# STM32G0B1 register map
File version: 1.8
CPU: CM0 r0p1, little endian, MPU, no FPU, 2 interrupt priority bits
Registers are 32-bit, read-write, reset 0x0 unless marked. A register's access mark holds for its fields unless they carry their own. Offsets are from the block's base; [hi:lo] are bit positions; {n}, {i} and the like mark numbered series; 'fields as' and 'values as' point back to an identical list.

## SYSCFG — System configuration controller
Base 0x40010000
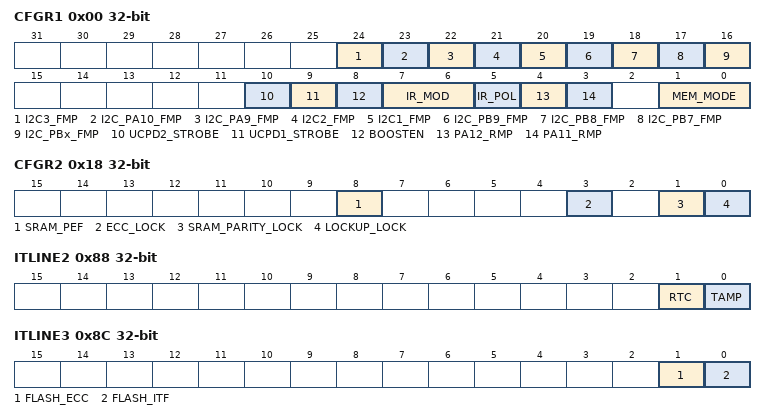
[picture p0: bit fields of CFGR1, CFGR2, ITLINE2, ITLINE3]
0x00 CFGR1 — SYSCFG configuration register 1
  [24] I2C3_FMP
    0=Disabled (Uses normal GPIO drive); 1=Enabled (Uses I2C FastMode+ drive)
  [23] I2C_PA10_FMP — Fast Mode Plus (FM+) driving capability activation bits
    values as I2C3_FMP
  [22] I2C_PA9_FMP — Fast Mode Plus (FM+) driving capability activation bits
    values as I2C3_FMP
  [21] I2C2_FMP — FM+ driving capability activation for I2C2
    values as I2C3_FMP
  [20] I2C1_FMP — FM+ driving capability activation for I2C1
    values as I2C3_FMP
  [19] I2C_PB9_FMP
    values as I2C3_FMP
  [18] I2C_PB8_FMP
    values as I2C3_FMP
  [17] I2C_PB7_FMP
    values as I2C3_FMP
  [16] I2C_PBx_FMP — Fast Mode Plus (FM+) driving capability activation bits
    values as I2C3_FMP
  [10] UCPD2_STROBE — Strobe signal bit for UCPD2
    1=Disconnect the UCPD pull-down resistors
  [9] UCPD1_STROBE — Strobe signal bit for UCPD1
    1=Disconnect the UCPD pull-down resistors
  [8] BOOSTEN — I/O analog switch voltage booster enable
    0=VDD (supply analog switches from VDD); 1=BOOST (supply analog switches from dedicated voltage booster)
  [7:6] IR_MOD — IR Modulation Envelope signal selection.
    0=TIM16 (IR modulation envelope from TIM16); 1=USART1 (IR modulation envelope from USART1); 2=USART4 (IR modulation envelope from USART4)
  [5] IR_POL — IR output polarity selection
    0=Normal (Output of IRTIM is not inverted); 1=Inverted (Output of IRTIM is inverted)
  [4] PA12_RMP — PA11 and PA12 remapping bit.
    0=Normal (PA12 pin connected to PA12 GPIO); 1=Remap (PA12 pin connected to PA10 GPIO)
  [3] PA11_RMP
    0=Normal (PA11 pin connected to PA11 GPIO); 1=Remap (PA11 pin connected to PA9 GPIO)
  [1:0] MEM_MODE — Memory mapping selection bits
    0=Main flash memory mapped at zero address; 2=System flash memory mapped at zero address; 3=SRAM (Embedded SRAM mapped at zero address)
0x18 CFGR2 — SYSCFG configuration register 1
  [8] SRAM_PEF — SRAM parity error flag
    0=Normal (No SRAM parity error detected); 1=Error (SRAM parity error detected)
  [3] ECC_LOCK — ECC error lock bit
    0=Disabled (error not connected to timers); 1=Enabled (error triggers TIM1/15/16/17 break input)
  [1] SRAM_PARITY_LOCK — SRAM parity lock bit
    values as ECC_LOCK
  [0] LOCKUP_LOCK — Cortex-M0+ LOCKUP bit enable bit
    values as ECC_LOCK
0x80 ITLINE0 ro — interrupt line 0 status register
  [0] WWDG — Window watchdog interrupt pending flag
    0=NotInterrupted (Interrupt not triggered); 1=Interrupted (Interrup triggered)
0x88 ITLINE2 ro — interrupt line 2 status register
  [1] RTC
    values as ITLINE0.WWDG
  [0] TAMP
    values as ITLINE0.WWDG
0x8C ITLINE3 ro — interrupt line 3 status register
  [1] FLASH_ECC
    values as ITLINE0.WWDG
  [0] FLASH_ITF
    values as ITLINE0.WWDG
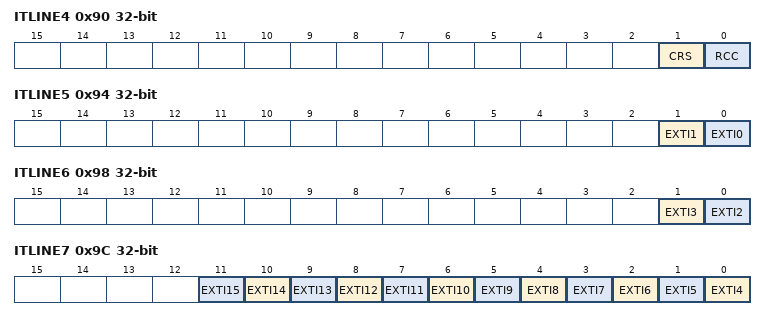
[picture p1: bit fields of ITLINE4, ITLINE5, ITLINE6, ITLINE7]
0x90 ITLINE4 ro — interrupt line 4 status register
  [1] CRS
    values as ITLINE0.WWDG
  [0] RCC
    values as ITLINE0.WWDG
0x94 ITLINE5 ro — interrupt line 5 status register
  [1] EXTI1
    values as ITLINE0.WWDG
  [0] EXTI0
    values as ITLINE0.WWDG
0x98 ITLINE6 ro — interrupt line 6 status register
  [1] EXTI3
    values as ITLINE0.WWDG
  [0] EXTI2
    values as ITLINE0.WWDG
0x9C ITLINE7 ro — interrupt line 7 status register
  [all] fields
    values as ITLINE0.WWDG
  [n-4] EXTI{n} (n=4..15)
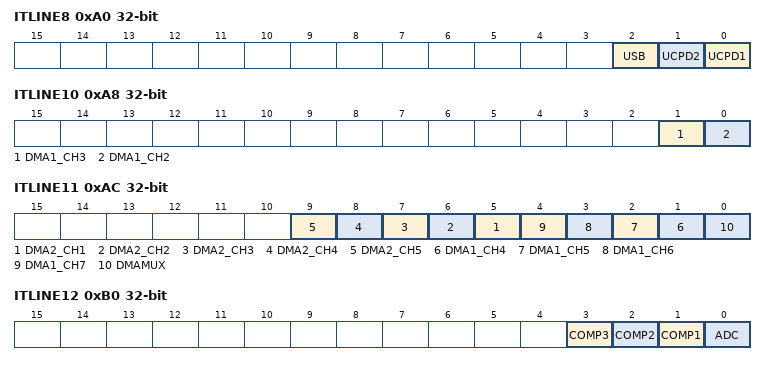
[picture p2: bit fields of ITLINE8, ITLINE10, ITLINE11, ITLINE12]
0xA0 ITLINE8 ro — interrupt line 8 status register
  [all] fields
    values as ITLINE0.WWDG
  [2] USB
  [1] UCPD2
  [0] UCPD1
0xA4 ITLINE9 ro — interrupt line 9 status register
  [0] DMA1_CH1
    values as ITLINE0.WWDG
0xA8 ITLINE10 ro — interrupt line 10 status register
  [1] DMA1_CH3
    values as ITLINE0.WWDG
  [0] DMA1_CH2 — DMA1_CH1
    values as ITLINE0.WWDG
0xAC ITLINE11 ro — interrupt line 11 status register
  [all] fields
    values as ITLINE0.WWDG
  [n+4] DMA2_CH{n} (n=1..5)
  [n-3] DMA1_CH{n} (n=4..7)
  [0] DMAMUX
0xB0 ITLINE12 ro — interrupt line 12 status register
  [all] fields
    values as ITLINE0.WWDG
  [3] COMP3
  [2] COMP2
  [1] COMP1
  [0] ADC
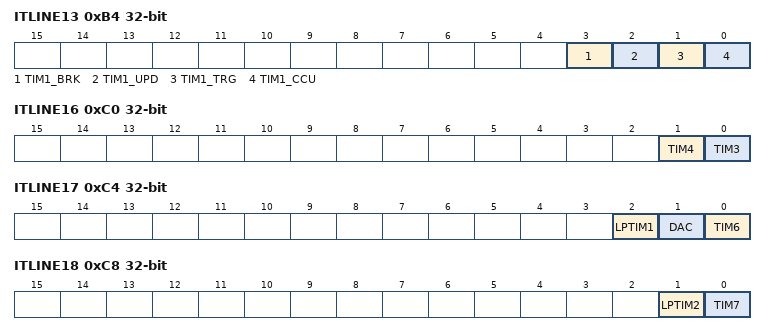
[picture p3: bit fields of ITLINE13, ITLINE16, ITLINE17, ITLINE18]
0xB4 ITLINE13 ro — interrupt line 13 status register
  [all] fields
    values as ITLINE0.WWDG
  [3] TIM1_BRK
  [2] TIM1_UPD
  [1] TIM1_TRG
  [0] TIM1_CCU
0xB8 ITLINE14 ro — interrupt line 14 status register
  [0] TIM1_CC
    values as ITLINE0.WWDG
0xBC ITLINE15 ro — interrupt line 15 status register
  [0] TIM2
    values as ITLINE0.WWDG
0xC0 ITLINE16 ro — interrupt line 16 status register
  [1] TIM4
    values as ITLINE0.WWDG
  [0] TIM3
    values as ITLINE0.WWDG
0xC4 ITLINE17 ro — interrupt line 17 status register
  [all] fields
    values as ITLINE0.WWDG
  [2] LPTIM1
  [1] DAC
  [0] TIM6
0xC8 ITLINE18 ro — interrupt line 18 status register
  [1] LPTIM2
    values as ITLINE0.WWDG
  [0] TIM7
    values as ITLINE0.WWDG
0xCC ITLINE19 ro — interrupt line 19 status register
  [0] TIM14
    values as ITLINE0.WWDG
0xD0 ITLINE20 ro — interrupt line 20 status register
  [0] TIM15
    values as ITLINE0.WWDG
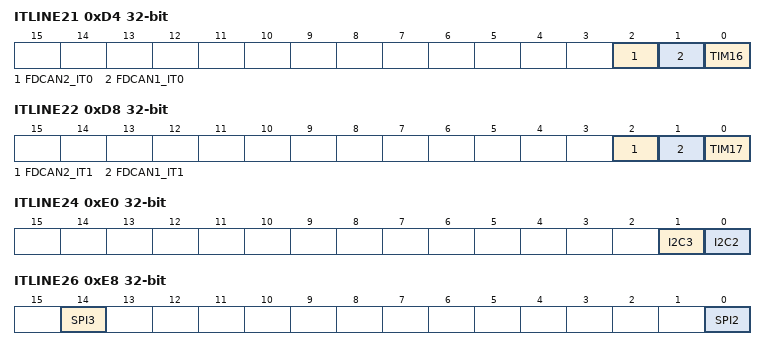
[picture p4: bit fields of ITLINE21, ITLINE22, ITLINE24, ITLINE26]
0xD4 ITLINE21 ro — interrupt line 21 status register
  [all] fields
    values as ITLINE0.WWDG
  [2] FDCAN2_IT0
  [1] FDCAN1_IT0
  [0] TIM16
0xD8 ITLINE22 ro — interrupt line 22 status register
  [all] fields
    values as ITLINE0.WWDG
  [2] FDCAN2_IT1
  [1] FDCAN1_IT1
  [0] TIM17
0xDC ITLINE23 ro — interrupt line 23 status register
  [0] I2C1
    values as ITLINE0.WWDG
0xE0 ITLINE24 ro — interrupt line 24 status register
  [1] I2C3
    values as ITLINE0.WWDG
  [0] I2C2
    values as ITLINE0.WWDG
0xE4 ITLINE25 ro — interrupt line 25 status register
  [0] SPI1
    values as ITLINE0.WWDG
0xE8 ITLINE26 ro — interrupt line 26 status register
  [14] SPI3
    values as ITLINE0.WWDG
  [0] SPI2
    values as ITLINE0.WWDG
0xEC ITLINE27 ro — interrupt line 27 status register
  [0] USART1
    values as ITLINE0.WWDG
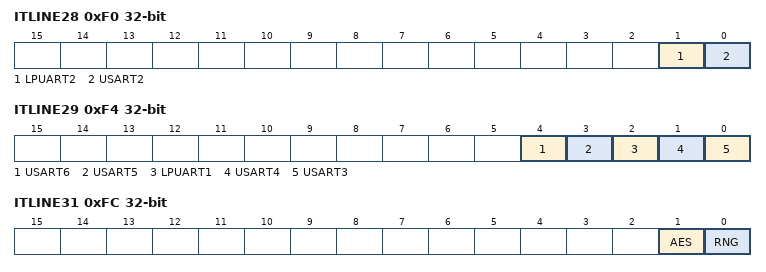
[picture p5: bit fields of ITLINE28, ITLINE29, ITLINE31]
0xF0 ITLINE28 ro — interrupt line 28 status register
  [1] LPUART2
    values as ITLINE0.WWDG
  [0] USART2
    values as ITLINE0.WWDG
0xF4 ITLINE29 ro — interrupt line 29 status register
  [all] fields
    values as ITLINE0.WWDG
  [4] USART6
  [3] USART5
  [2] LPUART1
  [1] USART4
  [0] USART3
0xF8 ITLINE30 ro — interrupt line 25 status register
  [0] CEC
    values as ITLINE0.WWDG
0xFC ITLINE31 ro — interrupt line 25 status register
  [1] AES
    values as ITLINE0.WWDG
  [0] RNG
    values as ITLINE0.WWDG
